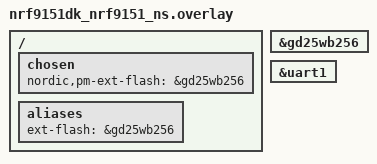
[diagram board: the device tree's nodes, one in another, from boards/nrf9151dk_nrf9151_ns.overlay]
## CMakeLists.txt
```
#
# Copyright (c) 2024 Nordic Semiconductor ASA
#
# SPDX-License-Identifier: LicenseRef-Nordic-5-Clause
#

cmake_minimum_required(VERSION 3.20.0)

find_package(Zephyr REQUIRED HINTS $ENV{ZEPHYR_BASE})
project("Asset Tracker Template")

# Include files that are common for all modules
target_include_directories(app PRIVATE src/common)

zephyr_include_directories(config)
zephyr_include_directories(src)
zephyr_include_directories(src/modules)

# Add main application source
target_sources(app PRIVATE src/main.c)

# Module source folders
add_subdirectory(src/modules/network)
add_subdirectory(src/modules/button)
add_subdirectory(src/cbor)

# Optional modules
add_subdirectory_ifdef(CONFIG_APP_POWER src/modules/power)
add_subdirectory_ifdef(CONFIG_APP_ENVIRONMENTAL src/modules/environmental)
add_subdirectory_ifdef(CONFIG_APP_LED src/modules/led)
add_subdirectory_ifdef(CONFIG_APP_LOCATION src/modules/location)
add_subdirectory_ifdef(CONFIG_APP_CLOUD src/modules/cloud)
add_subdirectory_ifdef(CONFIG_APP_FOTA src/modules/fota)
```

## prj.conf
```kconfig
#
# Copyright (c) 2024 Nordic Semiconductor ASA
#
# SPDX-License-Identifier: LicenseRef-Nordic-5-Clause
#

CONFIG_NCS_APPLICATION_BOOT_BANNER_STRING="Asset Tracker Template"
CONFIG_NCS_SAMPLES_DEFAULTS=y
CONFIG_RESET_ON_FATAL_ERROR=y
CONFIG_LOG_MODE_DEFERRED=y
CONFIG_LOG_BUFFER_SIZE=4096
CONFIG_LOG_PROCESS_THREAD_STACK_SIZE=768
CONFIG_DK_LIBRARY=y
CONFIG_ZVFS_OPEN_MAX=10
CONFIG_PWM=y

# TFM logging over uart0
CONFIG_TFM_LOG_LEVEL_SILENCE=n
CONFIG_TFM_SECURE_UART0=y
CONFIG_TFM_SECURE_UART_SHARE_INSTANCE=y
CONFIG_TFM_EXCEPTION_INFO_DUMP=y
CONFIG_TFM_SPM_LOG_LEVEL_DEBUG=y

# Heap and stacks
CONFIG_MAIN_STACK_SIZE=1856
# Extended AT host/monitor stack/heap sizes since some nrf_cloud credentials are longer than 1024 bytes.
CONFIG_AT_MONITOR_HEAP_SIZE=2176
CONFIG_HEAP_MEM_POOL_SIZE=10000
CONFIG_HEAP_MEM_POOL_IGNORE_MIN=y
CONFIG_SYSTEM_WORKQUEUE_STACK_SIZE=1280

# Enable Networking and Connection Manager.
CONFIG_NETWORKING=y
CONFIG_NET_SOCKETS=y
CONFIG_NET_SOCKETS_OFFLOAD=y
CONFIG_POSIX_API=y

# Enable LTE Connectivity using Connection Manager
CONFIG_NET_IPV4=y
CONFIG_NET_IPV6=y
CONFIG_NET_IPV6_NBR_CACHE=n
CONFIG_NET_IPV6_MLD=n
CONFIG_NET_CONNECTION_MANAGER=y
CONFIG_NET_CONNECTION_MANAGER_MONITOR_STACK_SIZE=384
CONFIG_NRF_MODEM_LIB_NET_IF=y
CONFIG_NRF_MODEM_LIB_NET_IF_AUTO_DOWN=y
CONFIG_NRF_MODEM_LIB_NET_IF_DOWN_DEFAULT_LTE_DISCONNECT=y

# Enable Link Controller modules
CONFIG_LTE_LC_PSM_MODULE=y
CONFIG_LTE_LC_EDRX_MODULE=y
CONFIG_LTE_LC_CONN_EVAL_MODULE=y

# Enable PSM (Power Saving Mode) - Temporarily disabled for testing responsiveness
CONFIG_LTE_LC_WORKQUEUE_STACK_SIZE=768
# CONFIG_LTE_PSM_REQ=y
# CONFIG_LTE_PROPRIETARY_PSM_REQ=y
# CONFIG_LTE_PSM_REQ_FORMAT_SECONDS=y
# PSM parameters (commented out while PSM is disabled for testing)
# CONFIG_LTE_PSM_REQ_RPTAU_SECONDS=7200
# CONFIG_LTE_PSM_REQ_RAT_SECONDS=30

# Enable eDRX (Extended Discontinuous Reception) with faster intervals
CONFIG_LTE_EDRX_REQ=y
# "0001" is 10.24 s - faster than default but still power efficient
CONFIG_LTE_EDRX_REQ_VALUE_LTE_M="0001"
CONFIG_LTE_EDRX_REQ_VALUE_NBIOT="0001"

# Modem library
CONFIG_NRF_MODEM_LIB=y

# AT commands interface
CONFIG_UART_INTERRUPT_DRIVEN=y
CONFIG_SHELL=y
CONFIG_SHELL_WILDCARD=n
CONFIG_SHELL_STACK_SIZE=2048
CONFIG_SHELL_CMD_BUFF_SIZE=2048
CONFIG_SHELL_BACKEND_SERIAL_RX_RING_BUFFER_SIZE=2048
CONFIG_AT_SHELL=y
CONFIG_LTE_SHELL=n

# nRF Cloud
CONFIG_NRF_CLOUD=y
CONFIG_NRF_CLOUD_COAP=y
CONFIG_NRF_CLOUD_COAP_DISCONNECT_ON_FAILED_REQUEST=y
CONFIG_MODEM_JWT=y
CONFIG_NRF_CLOUD_PRINT_DETAILS=n

# On initial connection to the cloud, add info sections to the shadow
CONFIG_MODEM_INFO=y
CONFIG_MODEM_INFO_ADD_DEVICE=y
CONFIG_NRF_CLOUD_SEND_DEVICE_STATUS=y
CONFIG_NRF_CLOUD_SEND_DEVICE_STATUS_NETWORK=y
CONFIG_NRF_CLOUD_SEND_DEVICE_STATUS_SIM=y
CONFIG_NRF_CLOUD_SEND_SERVICE_INFO_FOTA=y

# MCUBOOT - Needed by FOTA
CONFIG_BOOTLOADER_MCUBOOT=y
CONFIG_IMG_MANAGER=y
CONFIG_MCUBOOT_IMG_MANAGER=y
CONFIG_STREAM_FLASH_ERASE=y

# Date Time lib - Used by PGPS and main application
CONFIG_DATE_TIME=y
CONFIG_DATE_TIME_THREAD_STACK_SIZE=576

CONFIG_SETTINGS=y
CONFIG_SETTINGS_FCB=y
CONFIG_FCB=y

# Downloader - used by FOTAS
CONFIG_DOWNLOADER=y
CONFIG_DOWNLOADER_STACK_SIZE=1664

# Flash - Used by FOTA
CONFIG_FLASH=y
CONFIG_FLASH_PAGE_LAYOUT=y
CONFIG_FLASH_MAP=y
CONFIG_STREAM_FLASH=y
CONFIG_MPU_ALLOW_FLASH_WRITE=y
CONFIG_NRF_CLOUD_LOG_DIRECT=n
CONFIG_NRF_CLOUD_LOG_OUTPUT_LEVEL=3
CONFIG_NRF_CLOUD_FOTA_POLL=y
CONFIG_NRF_CLOUD_FOTA_POLL_LOG_LEVEL_DBG=y
CONFIG_NRF_CLOUD_FOTA_FULL_MODEM_UPDATE=y
CONFIG_NRF_CLOUD_FOTA_DOWNLOAD_FRAGMENT_SIZE=1900
CONFIG_NRF_CLOUD_COAP_DOWNLOADS=y
CONFIG_FOTA_DOWNLOAD=y
CONFIG_FOTA_DOWNLOAD_PROGRESS_EVT=y
CONFIG_FOTA_DL_TIMEOUT_MIN=30
CONFIG_DFU_TARGET=y

# Credentials
CONFIG_NRF_CLOUD_CLIENT_ID_SRC_INTERNAL_UUID=y
CONFIG_NRF_CLOUD_CHECK_CREDENTIALS=y
CONFIG_NRF_CLOUD_CREDENTIALS_MGMT_MODEM=y

# COAP client
CONFIG_COAP_MAX_RETRANSMIT=2
# Set CoAP therad to same priority as other modules
CONFIG_COAP_CLIENT_THREAD_PRIORITY=14
CONFIG_COAP_CLIENT_BLOCK_SIZE=1024
CONFIG_COAP_CLIENT_MESSAGE_SIZE=1024
CONFIG_COAP_CLIENT_STACK_SIZE=1280
CONFIG_COAP_EXTENDED_OPTIONS_LEN_VALUE=192

# needed for processing floats
CONFIG_PICOLIBC=y
CONFIG_FPU=y

# Zbus
CONFIG_ZBUS=y
CONFIG_ZBUS_MSG_SUBSCRIBER=y
CONFIG_ZBUS_MSG_SUBSCRIBER_NET_BUF_POOL_SIZE=64
CONFIG_ZBUS_CHANNEL_NAME=y

# Zephyr State Machine Framework
CONFIG_SMF=y
CONFIG_SMF_ANCESTOR_SUPPORT=y
CONFIG_SMF_INITIAL_TRANSITION=y

# Location


CONFIG_LOCATION=y
CONFIG_LOCATION_DATA_DETAILS=y
CONFIG_LOCATION_METHOD_GNSS=y
CONFIG_LOCATION_SERVICE_NRF_CLOUD_GNSS_POS_SEND=y
CONFIG_LOCATION_REQUEST_DEFAULT_GNSS_TIMEOUT=60000
CONFIG_LOCATION_REQUEST_DEFAULT_CELLULAR_TIMEOUT=30000
CONFIG_LOCATION_REQUEST_DEFAULT_TIMEOUT=120000
CONFIG_LOCATION_REQUEST_DEFAULT_CELLULAR_CELL_COUNT=3
CONFIG_LOCATION_REQUEST_DEFAULT_GNSS_VISIBILITY_DETECTION=y
CONFIG_LTE_NETWORK_MODE_LTE_M_NBIOT_GPS=y
CONFIG_NRF_CLOUD_AGNSS=y

# Not for LTE throughput testing
CONFIG_NRF_MODEM_LIB_SHMEM_TX_SIZE=4096
CONFIG_NRF_MODEM_LIB_SHMEM_RX_SIZE=4096

# For nRF9160 the default is socket interface
CONFIG_NET_DEFAULT_IF_ETHERNET=y
CONFIG_MBEDTLS=n

# Networking
CONFIG_NET_L2_ETHERNET=y
CONFIG_NET_NATIVE=y
CONFIG_NET_IPV4=y
CONFIG_NET_DHCPV4=y
CONFIG_NET_STATISTICS=y
CONFIG_NET_STATISTICS_USER_API=y
CONFIG_NET_CONTEXT_SYNC_RECV=y

# Memory configurations
CONFIG_NET_BUF_RX_COUNT=8
CONFIG_NET_BUF_TX_COUNT=8
CONFIG_NET_PKT_RX_COUNT=1
CONFIG_NET_PKT_TX_COUNT=1
CONFIG_NET_TX_STACK_SIZE=192
CONFIG_NET_RX_STACK_SIZE=192
CONFIG_NET_TC_TX_COUNT=1
CONFIG_NET_MAX_CONTEXTS=5
CONFIG_NET_MGMT_EVENT_STACK_SIZE=1280

# Needed due to using connectivity manager
CONFIG_NET_IF_MAX_IPV6_COUNT=2
CONFIG_NET_IF_MAX_IPV4_COUNT=2

# For debugging purposes
CONFIG_THREAD_NAME=y

# Extra Logging
CONFIG_APP_FOTA_LOG_LEVEL_DBG=y
CONFIG_APP_LOCATION_LOG_LEVEL_DBG=y
CONFIG_APP_CLOUD_LOG_LEVEL_DBG=y
CONFIG_APP_NETWORK_LOG_LEVEL_DBG=y
CONFIG_APP_LOG_LEVEL_DBG=y

# Task Watchdog
CONFIG_TASK_WDT=y
CONFIG_TASK_WDT_CHANNELS=8
CONFIG_TASK_WDT_MIN_TIMEOUT=10000

# Device power management
CONFIG_PM_DEVICE=y
CONFIG_PM_DEVICE_SHELL=y

CONFIG_APP_LED=y
CONFIG_LED=y
# Logging (for debugging)
CONFIG_LOG=y
CONFIG_APP_LED_LOG_LEVEL_DBG=y
# Set update interval to 60 seconds (1 minute)
CONFIG_APP_MODULE_TRIGGER_TIMEOUT_SECONDS=60
```

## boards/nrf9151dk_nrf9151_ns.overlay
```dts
/*
 * Copyright (c) 2025 Nordic Semiconductor ASA
 *
 * SPDX-License-Identifier: LicenseRef-Nordic-5-Clause
 */

/ {
	/* Configure partition manager to use gd25wb256 as the external flash */
	chosen {
		nordic,pm-ext-flash = &gd25wb256;
	};

	aliases {
		ext-flash = &gd25wb256;
	};
};

&gd25wb256 {
	status = "okay";
};

&uart1 {
	status = "okay";
};
```

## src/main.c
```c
/*
 * Copyright (c) 2024 Nordic Semiconductor ASA
 *
 * SPDX-License-Identifier: LicenseRef-Nordic-5-Clause
 */

#include <zephyr/kernel.h>
#include <zephyr/logging/log.h>
#include <zephyr/zbus/zbus.h>
#include <zephyr/task_wdt/task_wdt.h>
#include <zephyr/smf.h>
#include <zephyr/sys/reboot.h>

#include "app_common.h"
#include "button.h"
#include "network.h"
#include "cloud.h"
#include "fota.h"
#include "location.h"
#include "cbor_helper.h"
#include "modules/led/led.h"

#if defined(CONFIG_APP_LED)
#include "led.h"
#endif /* CONFIG_APP_LED */

#if defined(CONFIG_APP_ENVIRONMENTAL)
#include "environmental.h"
#endif /* CONFIG_APP_ENVIRONMENTAL */

#if defined(CONFIG_APP_POWER)
#include "power.h"
#endif /* CONFIG_APP_POWER */

/* Register log module */
LOG_MODULE_REGISTER(main, CONFIG_APP_LOG_LEVEL);

/* Register subscriber */
ZBUS_MSG_SUBSCRIBER_DEFINE(main_subscriber);

ZBUS_CHAN_DEFINE(TIMER_CHAN,
		 int,
		 NULL,
		 NULL,
		 ZBUS_OBSERVERS_EMPTY,
		 ZBUS_MSG_INIT(0)
);

static uint32_t update_interval = 60;

/* Define the channels that the module subscribes to, their associated message types
 * and the subscriber that will receive the messages on the channel.
 * We use the X-macros to make the code more maintainable.
 */
#define CHANNEL_LIST(X)						\
	X(CLOUD_CHAN,		struct cloud_msg)		\
	X(BUTTON_CHAN,		uint8_t)			\
	X(FOTA_CHAN,		enum fota_msg_type)		\
	X(NETWORK_CHAN,		struct network_msg)		\
	X(LOCATION_CHAN,	enum location_msg_type)		\
	X(TIMER_CHAN,		int)

/* Calculate the maximum message size from the list of channels */
#define MAX_MSG_SIZE				MAX_MSG_SIZE_FROM_LIST(CHANNEL_LIST)

/* Add main_subscriber as observer to all the channels in the list. */
#define ADD_OBSERVERS(_chan, _type)		ZBUS_CHAN_ADD_OBS(_chan, main_subscriber, 0);

/*
 * Expand to a call to ZBUS_CHAN_ADD_OBS for each channel in the list.
 * Example: ZBUS_CHAN_ADD_OBS(CLOUD_CHAN, main_subscriber, 0);
 */
CHANNEL_LIST(ADD_OBSERVERS)

/* Forward declarations */
static void timer_work_fn(struct k_work *work);

/* Delayable work used to schedule triggers */
static K_WORK_DELAYABLE_DEFINE(trigger_work, timer_work_fn);

/* Forward declarations of state handlers */
static void running_entry(void *o);
static void running_run(void *o);

static void triggering_entry(void *o);
static void triggering_run(void *o);

static void sample_data_entry(void *o);
static void sample_data_run(void *o);

static void wait_for_trigger_entry(void *o);
static void wait_for_trigger_run(void *o);
static void wait_for_trigger_exit(void *o);

static void idle_entry(void *o);
static void idle_run(void *o);

static void fota_entry(void *o);
static void fota_run(void *o);

static void fota_downloading_entry(void *o);
static void fota_downloading_run(void *o);

static void fota_waiting_for_network_disconnect_entry(void *o);
static void fota_waiting_for_network_disconnect_run(void *o);

static void fota_waiting_for_network_disconnect_to_apply_image_entry(void *o);
static void fota_waiting_for_network_disconnect_to_apply_image_run(void *o);

static void fota_applying_image_entry(void *o);
static void fota_applying_image_run(void *o);

static void fota_rebooting_entry(void *o);


enum state {
	/* Normal operation */
	STATE_RUNNING,
		/* Disconnected from the cloud, no triggers are sent */
		STATE_IDLE,
		/* Triggers are periodically sent at a configured interval */
		STATE_TRIGGERING,
			/* Requesting data samples from relevant modules.
			 * Location data is requested first, upon state entry.
			 * After location data is received, the other modules are polled.
			 */
			STATE_SAMPLE_DATA,
			/* Wait for timer or button press to trigger the next sample */
			STATE_WAIT_FOR_TRIGGER,
	/* Ongoing FOTA process, triggers are blocked */
	STATE_FOTA,
		/* FOTA image is being downloaded */
		STATE_FOTA_DOWNLOADING,
		/* Disconnecting from the network */
		STATE_FOTA_WAITING_FOR_NETWORK_DISCONNECT,
		/* Waiting for network disconnect to apply the image, state needed for
		 * Full Modem FOTA. Extra step needed to apply the image before rebooting.
		 */
		STATE_FOTA_WAITING_FOR_NETWORK_DISCONNECT_TO_APPLY_IMAGE,
		/* Applying the image */
		STATE_FOTA_APPLYING_IMAGE,
		/* Rebooting */
		STATE_FOTA_REBOOTING,
};

/* State object for the app module.
 * Used to transfer data between state changes.
 */
struct main_state {
	/* This must be first */
	struct smf_ctx ctx;

	/* Last channel type that a message was received on */
	const struct zbus_channel *chan;

	/* Last received message */
	uint8_t msg_buf[MAX_MSG_SIZE];

	/* Trigger interval */
	uint32_t interval_sec;

	/* Cloud connection status */
	bool connected;

	/* Start time of the most recent sampling. This is used to calculate the correct
	 * time when scheduling the next sampling trigger.
	 */
	uint32_t sample_start_time;
};

/* Construct state table */
static const struct smf_state states[] = {
	[STATE_RUNNING] = SMF_CREATE_STATE(
		running_entry,
		running_run,
		NULL,
		NULL,
		&states[STATE_IDLE]
	),
	[STATE_IDLE] = SMF_CREATE_STATE(
		idle_entry,
		idle_run,
		NULL,
		&states[STATE_RUNNING],
		NULL
	),
	[STATE_TRIGGERING] = SMF_CREATE_STATE(
		triggering_entry,
		triggering_run,
		NULL,
		&states[STATE_RUNNING],
		&states[STATE_SAMPLE_DATA]
	),
	[STATE_SAMPLE_DATA] = SMF_CREATE_STATE(
		sample_data_entry,
		sample_data_run,
		NULL,
		&states[STATE_TRIGGERING],
		NULL
	),
	[STATE_WAIT_FOR_TRIGGER] = SMF_CREATE_STATE(
		wait_for_trigger_entry,
		wait_for_trigger_run,
		wait_for_trigger_exit,
		&states[STATE_TRIGGERING],
		NULL
	),
	[STATE_FOTA] = SMF_CREATE_STATE(
		fota_entry,
		fota_run,
		NULL,
		NULL,
		&states[STATE_FOTA_DOWNLOADING]
	),
	[STATE_FOTA_DOWNLOADING] = SMF_CREATE_STATE(
		fota_downloading_entry,
		fota_downloading_run,
		NULL,
		&states[STATE_FOTA],
		NULL
	),
	[STATE_FOTA_WAITING_FOR_NETWORK_DISCONNECT] = SMF_CREATE_STATE(
		fota_waiting_for_network_disconnect_entry,
		fota_waiting_for_network_disconnect_run,
		NULL,
		&states[STATE_FOTA],
		NULL
	),
	[STATE_FOTA_WAITING_FOR_NETWORK_DISCONNECT_TO_APPLY_IMAGE] = SMF_CREATE_STATE(
		fota_waiting_for_network_disconnect_to_apply_image_entry,
		fota_waiting_for_network_disconnect_to_apply_image_run,
		NULL,
		&states[STATE_FOTA],
		NULL
	),
	[STATE_FOTA_APPLYING_IMAGE] = SMF_CREATE_STATE(
		fota_applying_image_entry,
		fota_applying_image_run,
		NULL,
		&states[STATE_FOTA],
		NULL
	),
	[STATE_FOTA_REBOOTING] = SMF_CREATE_STATE(
		fota_rebooting_entry,
		NULL,
		NULL,
		&states[STATE_FOTA],
		NULL
	),
};

/* Static helper function */

static void task_wdt_callback(int channel_id, void *user_data)
{
	LOG_ERR("Watchdog expired, Channel: %d, Thread: %s",
		channel_id, k_thread_name_get((k_tid_t)user_data));

	SEND_FATAL_ERROR_WATCHDOG_TIMEOUT();
}

static void sensor_and_poll_triggers_send(void)
{
	int err;
	struct cloud_msg cloud_msg = {
		.type = CLOUD_POLL_SHADOW
	};

	err = zbus_chan_pub(&CLOUD_CHAN, &cloud_msg, K_SECONDS(1));
	if (err) {
		LOG_ERR("zbus_chan_pub shadow trigger, error: %d", err);
		SEND_FATAL_ERROR();
		return;
	}

#if defined(CONFIG_APP_REQUEST_NETWORK_QUALITY)
	struct network_msg network_msg = {
		.type = NETWORK_QUALITY_SAMPLE_REQUEST,
	};

	err = zbus_chan_pub(&NETWORK_CHAN, &network_msg, K_SECONDS(1));
	if (err) {
		LOG_ERR("zbus_chan_pub, error: %d", err);
		SEND_FATAL_ERROR();
		return;
	}
#endif /* CONFIG_APP_REQUEST_NETWORK_QUALITY */

#if defined(CONFIG_APP_POWER)
	struct power_msg power_msg = {
		.type = POWER_BATTERY_PERCENTAGE_SAMPLE_REQUEST,
	};

	err = zbus_chan_pub(&POWER_CHAN, &power_msg, K_SECONDS(1));
	if (err) {
		LOG_ERR("zbus_chan_pub, error: %d", err);
		SEND_FATAL_ERROR();
		return;
	}
#endif /* CONFIG_APP_POWER */

#if defined(CONFIG_APP_ENVIRONMENTAL)
	struct environmental_msg environmental_msg = {
		.type = ENVIRONMENTAL_SENSOR_SAMPLE_REQUEST,
	};

	err = zbus_chan_pub(&ENVIRONMENTAL_CHAN, &environmental_msg, K_SECONDS(1));
	if (err) {
		LOG_ERR("zbus_chan_pub, error: %d", err);
		SEND_FATAL_ERROR();
		return;
	}
#endif /* CONFIG_APP_ENVIRONMENTAL */

	/* Send FOTA poll trigger */
	enum fota_msg_type fota_msg = FOTA_POLL_REQUEST;

	err = zbus_chan_pub(&FOTA_CHAN, &fota_msg, K_SECONDS(1));
	if (err) {
		LOG_ERR("zbus_chan_pub FOTA trigger, error: %d", err);
		SEND_FATAL_ERROR();
		return;
	}
}

/* Delayable work used to send messages on the TIMER_CHAN */
static void timer_work_fn(struct k_work *work)
{
	int err;
	int dummy = 0;

	ARG_UNUSED(work);

	err = zbus_chan_pub(&TIMER_CHAN, &dummy, K_SECONDS(1));
	if (err) {
		LOG_ERR("zbus_chan_pub, error: %d", err);
		SEND_FATAL_ERROR();
		return;
	}
}

/* Zephyr State Machine framework handlers */

/* STATE_RUNNING */

static void running_entry(void *o)
{
	const struct main_state *state_object = (const struct main_state *)o;

	LOG_DBG("%s", __func__);

	if (state_object->connected) {
		smf_set_state(SMF_CTX(state_object), &states[STATE_TRIGGERING]);
		return;
	}

	smf_set_state(SMF_CTX(state_object), &states[STATE_IDLE]);
}

static void running_run(void *o)
{
	const struct main_state *state_object = (const struct main_state *)o;

	if (state_object->chan == &FOTA_CHAN) {
		enum fota_msg_type msg = MSG_TO_FOTA_TYPE(state_object->msg_buf);

		if (msg == FOTA_DOWNLOADING_UPDATE) {
			smf_set_state(SMF_CTX(state_object), &states[STATE_FOTA]);
			return;
		}
	}
}

/* STATE_IDLE */

static void idle_entry(void *o)
{
	ARG_UNUSED(o);

	LOG_DBG("%s", __func__);

/* Commented out hardcoded LED patterns to avoid interfering with cloud-controlled LEDs */
#if 0 // defined(CONFIG_APP_LED)
	int err;
	/* Blink Yellow */
	struct led_msg led_msg = {
		.type = LED_RGB_SET,
		.red = 255,
		.green = 255,
		.blue = 0,
		.duration_on_msec = 250,
		.duration_off_msec = 2000,
		.repetitions = 10,
	};

	err = zbus_chan_pub(&LED_CHAN, &led_msg, K_SECONDS(1));
	if (err) {
		LOG_ERR("zbus_chan_pub, error: %d", err);
		SEND_FATAL_ERROR();
		return;
	}
#endif /* CONFIG_APP_LED */

	(void)k_work_cancel_delayable(&trigger_work);
}

static void idle_run(void *o)
{
	struct main_state *state_object = o;

	if (state_object->chan == &CLOUD_CHAN) {
		const struct cloud_msg *msg = MSG_TO_CLOUD_MSG_PTR(state_object->msg_buf);

		if (msg->type == CLOUD_CONNECTED) {
			state_object->connected = true;
			smf_set_state(SMF_CTX(state_object), &states[STATE_TRIGGERING]);
			return;
		}
	}
}

/* STATE_CONNECTED */

static void triggering_entry(void *o)
{
	int err;

	ARG_UNUSED(o);

	LOG_DBG("%s", __func__);

	err = k_work_reschedule(&trigger_work, K_NO_WAIT);
	if (err < 0) {
		LOG_ERR("k_work_reschedule, error: %d", err);
		SEND_FATAL_ERROR();
		return;
	}
}

static void triggering_run(void *o)
{
	int err;
	struct main_state *state_object = o;

	if (state_object->chan == &CLOUD_CHAN) {
		const struct cloud_msg *msg = MSG_TO_CLOUD_MSG_PTR(state_object->msg_buf);

		if (msg->type == CLOUD_DISCONNECTED) {
			state_object->connected = false;
			smf_set_state(SMF_CTX(state_object), &states[STATE_IDLE]);
			return;
		}
		if (msg->type == CLOUD_SHADOW_RESPONSE) {
    		LOG_DBG("CLOUD_SHADOW_RESPONSE received");
    		
    		// Simple logging to avoid reset loop
    		LOG_INF("Shadow data received, length: %d bytes", msg->response.buffer_data_len);
    		LOG_HEXDUMP_INF(msg->response.buffer, msg->response.buffer_data_len, "Shadow CBOR data:");

    		// Process update interval (existing functionality)
    		uint32_t update_interval_new;
    		int err = get_update_interval_from_cbor_response(
        		msg->response.buffer,
        		msg->response.buffer_data_len,
        		&update_interval_new);

    	if (err == 0) {
        	update_interval = update_interval_new;
        	LOG_INF("Update interval set to %d seconds from cloud", update_interval);
    	}

    	// Process LED command (new functionality)
    	struct led_msg led_cmd;
    	err = get_led_command_from_cbor_response(
        	msg->response.buffer,
        	msg->response.buffer_data_len,
        	(void *)&led_cmd);

    	if (err == 0) {
        	LOG_INF("LED command received from cloud shadow");
        	err = zbus_chan_pub(&LED_CHAN, &led_cmd, K_SECONDS(3));
        if (err) {
            LOG_ERR("Failed to publish LED command, error: %d", err);
        } else {
            LOG_INF("LED command published successfully");
        }
    	} else if (err == -ENOENT) {
        	LOG_DBG("No LED configuration in shadow response");
    	} else {
        	LOG_ERR("Failed to parse LED command from shadow, error: %d", err);
    	}
	}
	}
}

/* STATE_SAMPLE_DATA */

static void sample_data_entry(void *o)
{
	int err;
	enum location_msg_type location_msg = LOCATION_SEARCH_TRIGGER;
	struct main_state *state_object = (struct main_state *)o;

	LOG_DBG("%s", __func__);

#if 0 // defined(CONFIG_APP_LED)
	/* Green pattern during active sampling */
	struct led_msg led_msg = {
		.type = LED_RGB_SET,
		.red = 0,
		.green = 55,
		.blue = 0,
		.duration_on_msec = 250,
		.duration_off_msec = 2000,
		.repetitions = 10,
	};

	err = zbus_chan_pub(&LED_CHAN, &led_msg, K_SECONDS(1));
	if (err) {
		LOG_ERR("zbus_chan_pub, error: %d", err);
		SEND_FATAL_ERROR();
		return;
	}
#endif /* CONFIG_APP_LED */

	/* Record the start time of sampling */
	state_object->sample_start_time = k_uptime_seconds();

	err = zbus_chan_pub(&LOCATION_CHAN, &location_msg, K_SECONDS(1));
	if (err) {
		LOG_ERR("zbus_chan_pub data sample trigger, error: %d", err);
		SEND_FATAL_ERROR();
		return;
	}
}

static void sample_data_run(void *o)
{
	const struct main_state *state_object = (const struct main_state *)o;

	if (state_object->chan == &LOCATION_CHAN) {
		enum location_msg_type msg = MSG_TO_LOCATION_TYPE(state_object->msg_buf);

		if (msg == LOCATION_SEARCH_DONE) {
			sensor_and_poll_triggers_send();
			smf_set_state(SMF_CTX(state_object), &states[STATE_WAIT_FOR_TRIGGER]);
			return;
		}
	}

	/* We are already sampling, ignore any new triggers */
	if (state_object->chan == &BUTTON_CHAN) {
		smf_set_handled(SMF_CTX(state_object));
		return;
	}

	if (state_object->chan == &TIMER_CHAN) {
		smf_set_handled(SMF_CTX(state_object));
		return;
	}
}

/* STATE_WAIT_FOR_TRIGGER */

static void wait_for_trigger_entry(void *o)
{
	int err;
	const struct main_state *state_object = (const struct main_state *)o;
	uint32_t time_elapsed = k_uptime_seconds() - state_object->sample_start_time;
	uint32_t time_remaining;

	if (time_elapsed > state_object->interval_sec) {
		LOG_WRN("Sampling took longer than the interval, skipping next trigger");
		time_remaining = 0;
	} else {
		time_remaining = state_object->interval_sec - time_elapsed;
	}

	LOG_DBG("%s", __func__);

	LOG_DBG("Next trigger in %d seconds", time_remaining);

	(void)k_work_cancel_delayable(&trigger_work);
	err = k_work_reschedule(&trigger_work, K_SECONDS(time_remaining));
	if (err < 0) {
		LOG_ERR("k_work_reschedule, error: %d", err);
		SEND_FATAL_ERROR();
	}

#if 0 // defined(CONFIG_APP_LED)
	/* Blue pattern for wait state */
	struct led_msg led_msg = {
		.type = LED_RGB_SET,
		.red = 0,
		.green = 0,
		.blue = 55,
		.duration_on_msec = 250,
		.duration_off_msec = 2000,
		.repetitions = 10,
	};

	err = zbus_chan_pub(&LED_CHAN, &led_msg, K_SECONDS(1));
	if (err) {
		LOG_ERR("zbus_chan_pub, error: %d", err);
		SEND_FATAL_ERROR();
		return;
	}
#endif /* CONFIG_APP_LED */


}

static void wait_for_trigger_run(void *o)
{
	const struct main_state *state_object = (const struct main_state *)o;

	if (state_object->chan == &TIMER_CHAN) {
		LOG_DBG("Timer trigger received");
		smf_set_state(SMF_CTX(state_object), &states[STATE_SAMPLE_DATA]);
		return;
	}

	if (state_object->chan == &BUTTON_CHAN) {
		smf_set_state(SMF_CTX(state_object), &states[STATE_SAMPLE_DATA]);
		return;
	}
}

static void wait_for_trigger_exit(void *o)
{
	ARG_UNUSED(o);

	LOG_DBG("%s", __func__);

	(void)k_work_cancel_delayable(&trigger_work);
}

/* STATE_FOTA */

static void fota_entry(void *o)
{
	ARG_UNUSED(o);

	LOG_DBG("%s", __func__);

	(void)k_work_cancel_delayable(&trigger_work);
}

static void fota_run(void *o)
{
	const struct main_state *state_object = (const struct main_state *)o;

	if (state_object->chan == &FOTA_CHAN) {
		enum fota_msg_type msg = MSG_TO_FOTA_TYPE(state_object->msg_buf);

		switch (msg) {
		case FOTA_DOWNLOAD_CANCELED:
			__fallthrough;
		case FOTA_DOWNLOAD_TIMED_OUT:
			__fallthrough;
		case FOTA_DOWNLOAD_FAILED:
			smf_set_state(SMF_CTX(state_object), &states[STATE_RUNNING]);
			return;
		default:
			/* Don't care */
			break;
		}
	}
}

/* STATE_FOTA_DOWNLOADING */

static void fota_downloading_entry(void *o)
{
	ARG_UNUSED(o);

	LOG_DBG("%s", __func__);

#if 0 // defined(CONFIG_APP_LED)
	int err;

	/* Purple pattern during download - indefinite for ongoing process */
	struct led_msg led_msg = {
		.type = LED_RGB_SET,
		.red = 160,
		.green = 32,
		.blue = 240,
		.duration_on_msec = 250,
		.duration_off_msec = 2000,
		.repetitions = -1,
	};

	err = zbus_chan_pub(&LED_CHAN, &led_msg, K_SECONDS(1));
	if (err) {
		LOG_ERR("zbus_chan_pub, error: %d", err);
		SEND_FATAL_ERROR();
		return;
	}
#endif /* CONFIG_APP_LED */
}

static void fota_downloading_run(void *o)
{
	const struct main_state *state_object = (const struct main_state *)o;

	if (state_object->chan == &FOTA_CHAN) {
		enum fota_msg_type msg = MSG_TO_FOTA_TYPE(state_object->msg_buf);

		switch (msg) {
		case FOTA_SUCCESS_REBOOT_NEEDED:
			smf_set_state(SMF_CTX(state_object),
					      &states[STATE_FOTA_WAITING_FOR_NETWORK_DISCONNECT]);
			return;
		case FOTA_IMAGE_APPLY_NEEDED:
			smf_set_state(SMF_CTX(state_object),
				&states[STATE_FOTA_WAITING_FOR_NETWORK_DISCONNECT_TO_APPLY_IMAGE]);
			return;
		default:
			/* Don't care */
			break;
		}
	}
}

/* STATE_FOTA_WAITING_FOR_NETWORK_DISCONNECT */

static void fota_waiting_for_network_disconnect_entry(void *o)
{
	int err;
	struct network_msg msg = {
		.type = NETWORK_DISCONNECT
	};

	ARG_UNUSED(o);

	LOG_DBG("%s", __func__);

	err = zbus_chan_pub(&NETWORK_CHAN, &msg, K_SECONDS(1));
	if (err) {
		LOG_ERR("zbus_chan_pub, error: %d", err);
		SEND_FATAL_ERROR();
	}
}

static void fota_waiting_for_network_disconnect_run(void *o)
{
	const struct main_state *state_object = (const struct main_state *)o;

	if (state_object->chan == &NETWORK_CHAN) {
		struct network_msg msg = MSG_TO_NETWORK_MSG(state_object->msg_buf);

		if (msg.type == NETWORK_DISCONNECTED) {
			smf_set_state(SMF_CTX(state_object), &states[STATE_FOTA_REBOOTING]);
			return;
		}
	}
}

/* STATE_FOTA_WAITING_FOR_NETWORK_DISCONNECT_TO_APPLY_IMAGE */

static void fota_waiting_for_network_disconnect_to_apply_image_entry(void *o)
{
	ARG_UNUSED(o);

	LOG_DBG("%s", __func__);

	int err;
	struct network_msg msg = {
		.type = NETWORK_DISCONNECT
	};

	err = zbus_chan_pub(&NETWORK_CHAN, &msg, K_SECONDS(1));
	if (err) {
		LOG_ERR("zbus_chan_pub, error: %d", err);
		SEND_FATAL_ERROR();
	}
}

static void fota_waiting_for_network_disconnect_to_apply_image_run(void *o)
{
	const struct main_state *state_object = (const struct main_state *)o;

	if (state_object->chan == &NETWORK_CHAN) {
		struct network_msg msg = MSG_TO_NETWORK_MSG(state_object->msg_buf);

		if (msg.type == NETWORK_DISCONNECTED) {
			smf_set_state(SMF_CTX(state_object), &states[STATE_FOTA_APPLYING_IMAGE]);
		}
	}
}

/* STATE_FOTA_APPLYING_IMAGE, */

static void fota_applying_image_entry(void *o)
{
	ARG_UNUSED(o);

	LOG_DBG("%s", __func__);

	int err;
	enum fota_msg_type msg = FOTA_IMAGE_APPLY;

	err = zbus_chan_pub(&FOTA_CHAN, &msg, K_SECONDS(1));
	if (err) {
		LOG_ERR("zbus_chan_pub, error: %d", err);
		SEND_FATAL_ERROR();
	}
}

static void fota_applying_image_run(void *o)
{
	const struct main_state *state_object = (const struct main_state *)o;

	if (state_object->chan == &FOTA_CHAN) {
		enum fota_msg_type msg = MSG_TO_FOTA_TYPE(state_object->msg_buf);

		if (msg == FOTA_SUCCESS_REBOOT_NEEDED) {
			smf_set_state(SMF_CTX(state_object), &states[STATE_FOTA_REBOOTING]);
			return;
		}
	}
}

/* STATE_FOTA_REBOOTING */

static void fota_rebooting_entry(void *o)
{
	ARG_UNUSED(o);

	LOG_DBG("%s", __func__);

	/* Reboot the device */
	LOG_WRN("Rebooting the device to apply the FOTA update");

	/* Flush log buffer */
	LOG_PANIC();

	k_sleep(K_SECONDS(5));

	sys_reboot(SYS_REBOOT_COLD);
}

int main(void)
{
	int err;
	int task_wdt_id;
	const uint32_t wdt_timeout_ms = (CONFIG_APP_WATCHDOG_TIMEOUT_SECONDS * MSEC_PER_SEC);
	const uint32_t execution_time_ms =
		(CONFIG_APP_MSG_PROCESSING_TIMEOUT_SECONDS * MSEC_PER_SEC);
	const k_timeout_t zbus_wait_ms = K_MSEC(wdt_timeout_ms - execution_time_ms);
	struct main_state main_state = { 0 };

	main_state.interval_sec = CONFIG_APP_MODULE_TRIGGER_TIMEOUT_SECONDS;

	LOG_DBG("Main has started");

	task_wdt_id = task_wdt_add(wdt_timeout_ms, task_wdt_callback, (void *)k_current_get());
	if (task_wdt_id < 0) {
		LOG_ERR("Failed to add task to watchdog: %d", task_wdt_id);
		SEND_FATAL_ERROR();
		return -EFAULT;
	}

	smf_set_initial(SMF_CTX(&main_state), &states[STATE_RUNNING]);

	while (1) {
		err = task_wdt_feed(task_wdt_id);
		if (err) {
			LOG_ERR("task_wdt_feed, error: %d", err);
			SEND_FATAL_ERROR();

			return err;
		}

		err = zbus_sub_wait_msg(&main_subscriber, &main_state.chan, main_state.msg_buf,
					zbus_wait_ms);
		if (err == -ENOMSG) {
			continue;
		} else if (err) {
			LOG_ERR("zbus_sub_wait_msg, error: %d", err);
			SEND_FATAL_ERROR();

			return err;
		}

		err = smf_run_state(SMF_CTX(&main_state));
		if (err) {
			LOG_ERR("smf_run_state(), error: %d", err);
			SEND_FATAL_ERROR();

			return err;
		}
	}
}
```
